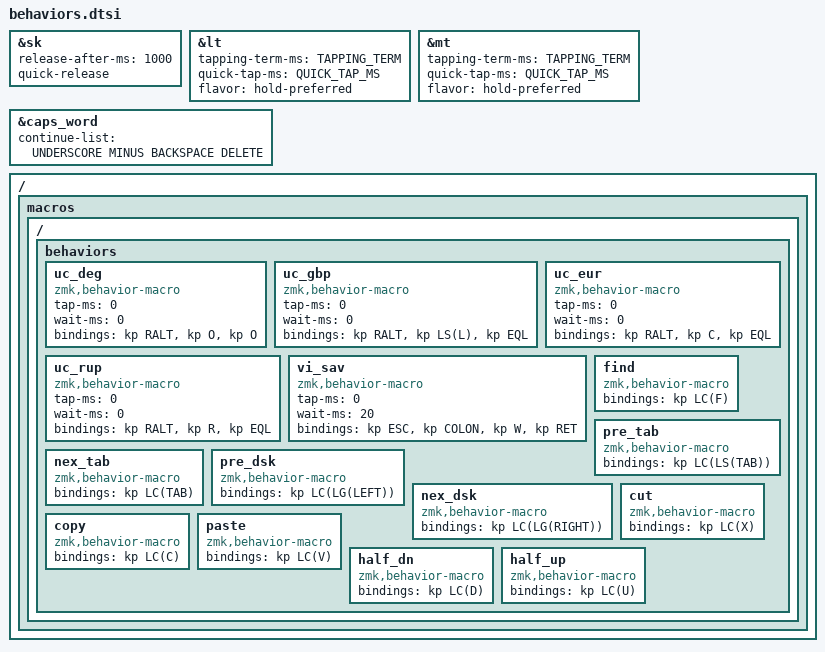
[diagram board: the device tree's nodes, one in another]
#include <behaviors.dtsi>
#include "helper.h"
#include "keys_en_gb_extended.h"

/* Homerow Mods */
#define PRIOR_IDLE_MS 180
#define QUICK_TAP_MS 250
#define TAPPING_TERM 300

#define MAKE_HT(NAME, MODE, HOLD, TAP, TRIGGER_POS) \
    ZMK_BEHAVIOR(NAME, hold_tap, \
        flavor = MODE; \
        tapping-term-ms = <TAPPING_TERM>; \
        quick-tap-ms = <QUICK_TAP_MS>; \
        bindings = <HOLD>, <TAP>; \
        require-prior-idle-ms = <PRIOR_IDLE_MS>; \
        hold-trigger-key-positions = <TRIGGER_POS>; \
        hold-trigger-on-release; \
    )


#define MAKE_HRM(NAME, HOLD, TAP, TRIGGER_POS) \
    MAKE_HT(NAME, "balanced", HOLD, TAP, TRIGGER_POS)

#define DEFAULT_COMBO(NAME, KEY, COMBO_KEYS) \
    ZMK_COMBO(NAME, KEY, COMBO_KEYS, COMBO_LAYERS, COMBO_TERM)

// The keys are fetched from the *_keys.h file sourced in the actual keymap before other includes
MAKE_HRM(hml, &kp, &kp, KEYS_R THUMBS)
MAKE_HRM(hmr, &kp, &kp, KEYS_L THUMBS)
MAKE_HRM(hll, &mo, &kp, KEYS_R THUMBS)
MAKE_HRM(hlr, &mo, &kp, KEYS_L THUMBS)

MAKE_HRM(mts, &sk, &caps_word, KEYS_L KEYS_R)
MAKE_HRM(mtb, &sk, &bsdel, KEYS_L KEYS_R)
MAKE_HRM(lts, &mo, &caps_word, KEYS_L KEYS_R)

MAKE_HT(thl, "tap-preferred", &mo, &kp, KEYS_L KEYS_R)
MAKE_HT(thm, "tap-preferred", &kp, &kp, KEYS_L KEYS_R)

MAKE_HT(lt_bsdel, "hold-preferred", &mo, &bsdel, KEYS_L KEYS_R)

&sk {
    release-after-ms = <1000>;
    quick-release;
};

/* All Other Behaviors */
&lt {
  tapping-term-ms = <TAPPING_TERM>;
  quick-tap-ms = <QUICK_TAP_MS>;
  flavor = "hold-preferred";
};

&mt {
  tapping-term-ms = <TAPPING_TERM>;
  quick-tap-ms = <QUICK_TAP_MS>;
  flavor = "hold-preferred";
};

&caps_word {
  continue-list = <UNDERSCORE MINUS BACKSPACE DELETE>;
};

/* This actually enables us to double tap the shift key to trigger caps_word. */
ZMK_BEHAVIOR(smart_sft, mod_morph,
    bindings = <&sk SFT>, <&caps_word>;
    mods = <(MOD_LSFT)>;
)

ZMK_BEHAVIOR(bsdel, mod_morph,
    bindings = <&kp BACKSPACE>, <&kp DELETE>;
    mods = <(MOD_LALT|MOD_LGUI|MOD_LSFT)>;
)

// tap: dollar ($) | shft + tap: pound (£)
ZMK_BEHAVIOR(dlr_gbp, mod_morph,
    bindings = <&kp DLLR>, <&uc_gbp>;
    mods = <(MOD_LSFT|MOD_RSFT)>;
)

// tap: hash (&) | shft + tap: eur (€)
ZMK_BEHAVIOR(amps_eur, mod_morph,
    bindings = <&kp AMPS>, <&uc_eur>;
    mods = <(MOD_LSFT|MOD_RSFT)>;
)

// tap: star (*) | shft + tap: rupee (₹)
ZMK_BEHAVIOR(star_rup, mod_morph,
    bindings = <&kp STAR>, <&uc_rup>;
    mods = <(MOD_LSFT|MOD_RSFT)>;
)

// alt-tab macro-pause from PR #1804. #1366 doesn't work any more
ZMK_BEHAVIOR(alt_tab, macro,
	        wait-ms = <0>;
          tap-ms = <0>;
          bindings
          = <&macro_press &kp LALT>
          , <&macro_tap &kp TAB>
          , <&macro_pause_for_layer>
          , <&macro_release &kp LALT>;
)

/* Combos
╭───────┬───────┬───────┬───────┬───────╮   ╭───────┬───────┬───────┬───────┬───────╮

├── ° ──┼─ &|€ ─┼── @ ──┼── ! ──┼── ` ──┤   ├── " ──┼── ' ──┼── - ──┼─ $|£ ─┼── % ──┤

├───────┼─ *|₹ ─┼── [ ──┼── ( ──┼── = ──┤   ├── \ ──┼── ) ──┼── ] ──┼─ #|~ ─┼── ^ ──┤

╰───────┼───────┼───────┼───────┼───────┤   ├───────┼───────┼───────┼───────┼───────┤
) */
// right side combos
DEFAULT_COMBO(backslash, &kp GB_DQT, RM0 RT0)
DEFAULT_COMBO(pipe, &kp GB_BSLH, RM0 RB0)

DEFAULT_COMBO(sqt, &kp SQT, RT1 RM1)
DEFAULT_COMBO(rpar, &kp RPAR, RM1 RB1)

DEFAULT_COMBO(minus, &kp MINUS, RT2 RM2)
DEFAULT_COMBO(rbkt, &kp RBKT, RM2 RB2)

DEFAULT_COMBO(dollar, &dlr_gbp, RT3 RM3)
DEFAULT_COMBO(hash, &kp GB_HASH, RM3 RB3)

DEFAULT_COMBO(perc, &kp PRCNT, RM4 RT4)
DEFAULT_COMBO(caret, &kp CARET, RM4 RB4)

// left side combos
DEFAULT_COMBO(tilde, &kp GRAVE, LT0 LM0)
DEFAULT_COMBO(equal, &kp EQUAL, LB0 LM0)

DEFAULT_COMBO(excl, &kp EXCL, LT1 LM1)
DEFAULT_COMBO(lpar, &kp LPAR, LM1 LB1)

DEFAULT_COMBO(at, &kp GB_AT, LT2 LM2)
DEFAULT_COMBO(lbkt, &kp LBKT, LM2 LB2)

DEFAULT_COMBO(amps, &amps_eur, LT3 LM3)
DEFAULT_COMBO(star, &star_rup, LB3 LM3)

DEFAULT_COMBO(degree, &uc_deg, LT4 LM4)

// horizontal combos
DEFAULT_COMBO(altl, &kp LALT, LB1 LB2)
DEFAULT_COMBO(altr, &kp LALT, RB1 RB2)

/* Macros */
/ {
  macros {
    ZMK_MACRO(uc_deg,  tap-ms=<0>                    ; wait-ms=<0> ; bindings = <&kp RALT>, <&kp O>,           <&kp O>  ;)
    ZMK_MACRO(uc_gbp,  tap-ms=<0>                    ; wait-ms=<0> ; bindings = <&kp RALT>, <&kp LS(L)>,       <&kp EQL>;)
    ZMK_MACRO(uc_eur,  tap-ms=<0>                    ; wait-ms=<0> ; bindings = <&kp RALT>, <&kp C>,           <&kp EQL>;)
    ZMK_MACRO(uc_rup,  tap-ms=<0>                    ; wait-ms=<0> ; bindings = <&kp RALT>, <&kp R>,           <&kp EQL>;)
    ZMK_MACRO(vi_sav,  tap-ms=<0>                    ; wait-ms=<20>; bindings = <&kp ESC>,  <&kp COLON &kp W>, <&kp RET>;)
    ZMK_MACRO(find,    bindings = <&kp LC(F)>        ;)
    ZMK_MACRO(pre_tab, bindings = <&kp LC(LS(TAB))>  ;)
    ZMK_MACRO(nex_tab, bindings = <&kp LC(TAB)>      ;)
    ZMK_MACRO(pre_dsk, bindings = <&kp LC(LG(LEFT))> ;)
    ZMK_MACRO(nex_dsk, bindings = <&kp LC(LG(RIGHT))>;)
    ZMK_MACRO(cut,     bindings = <&kp LC(X)>        ;)
    ZMK_MACRO(copy,    bindings = <&kp LC(C)>        ;)
    ZMK_MACRO(paste,   bindings = <&kp LC(V)>        ;)
    ZMK_MACRO(half_dn, bindings = <&kp LC(D)>        ;)
    ZMK_MACRO(half_up, bindings = <&kp LC(U)>        ;)
  };
};
